# CONTROLSS_G3_EPWM24_CONTROLSS_G3_EPWM24 register map
Vendor: Texas Instruments
Registers are 16-bit, read-write, reset values left out (the file's numbers can be read two ways) unless marked. A register's access mark holds for its fields unless they carry their own. Offsets are as the file gives them; [hi:lo] are bit positions; {n}, {i} and the like mark numbered series.

## CONTROLSS_G3_EPWM24_CONTROLSS_G3_EPWM24 (part 4 of 4)
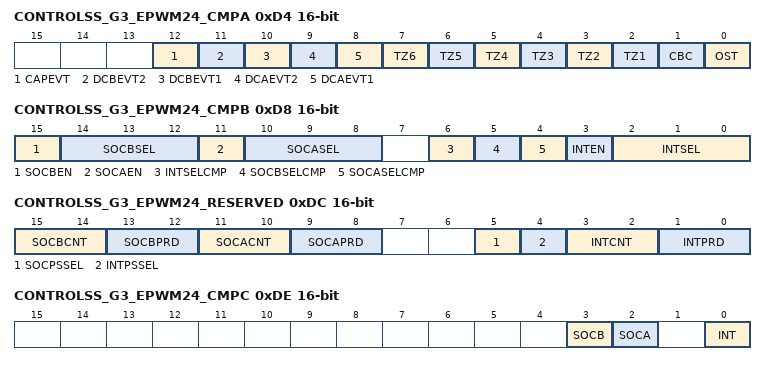
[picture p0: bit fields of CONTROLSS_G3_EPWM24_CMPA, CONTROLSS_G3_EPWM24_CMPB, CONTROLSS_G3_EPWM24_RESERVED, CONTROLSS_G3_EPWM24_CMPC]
0xD4 CONTROLSS_G3_EPWM24_CMPA
  [12] CAPEVT — CAPEVT Select 0: Disable TZ6 as a TRIPOUT source for this ePWM module 1: Enable TZ6 as a TRIPOUT source for this ePWM module
  [11] DCBEVT2 — DCBEVT2 Select 0: Disable TZ6 as a TRIPOUT source for this ePWM module 1: Enable TZ6 as a TRIPOUT source for this ePWM module
  [10] DCBEVT1 — DCBEVT1 Select 0: Disable TZ6 as a TRIPOUT source for this ePWM module 1: Enable TZ6 as a TRIPOUT source for this ePWM module
  [9] DCAEVT2 — DCAEVT2 Select 0: Disable TZ6 as a TRIPOUT source for this ePWM module 1: Enable TZ6 as a TRIPOUT source for this ePWM module
  [8] DCAEVT1 — DCAEVT1 Select 0: Disable TZ6 as a TRIPOUT source for this ePWM module 1: Enable TZ6 as a TRIPOUT source for this ePWM module
  [n+1] TZ{n} (n=1..6) — Trip-zone {n} (TZ{n}) Select 0: Disable TZ{n} as a TRIPOUT source for this ePWM module 1: Enable TZ{n} as a TRIPOUT source for this ePWM module
  [1] CBC — CBC Select 0: Disable TZ1 as a TRIPOUT source for this ePWM module 1: Enable TZ1 as a TRIPOUT source for this ePWM module
  [0] OST — OST Select 0: Disable TZ1 as a TRIPOUT source for this ePWM module 1: Enable TZ1 as a TRIPOUT source for this ePWM module
0xD8 CONTROLSS_G3_EPWM24_CMPB
  [15] SOCBEN — Enable the ADC Start of Conversion B (EPWMxSOCB) Pulse 0: Disable EPWMxSOCB. 1: Enable EPWMxSOCB pulse.
  [14:12] SOCBSEL — EPWMxSOCB Selection Options These bits determine when a EPWMxSOCB pulse will be generated. 000: Enable DCBEVT1.soc event 001: Enable event time-base counter equal to zero. (TBCTR = 0x00) 010: Enable event time-base counter equal to period (TBCTR = TBPRD) 011: Enable event time-base counter based on mixed events (ETSOCBMIX). ETSOCBMIX is configured in the ETSOCBMIXEN register. 100: Enable event time-base counter equal to CMPA when the timer is incrementing or CMPC when the timer is incrementing 101: Enable event time-base counter equal to CMPA when the timer is decrementing or CMPC when the timer is decrementing 110: Enable event: time-base counter equal to CMPB when the timer is incrementing or CMPD when the timer is incrementing 111: Enable event: time-base counter equal to CMPB when the timer is decrementing or CMPD when the timer is decrementing (*) Event selected is determined by SOCBSELCMP bit.
  [11] SOCAEN — Enable the ADC Start of Conversion A (EPWMxSOCA) Pulse 0: Disable EPWMxSOCA. 1: Enable EPWMxSOCA pulse.
  [10:8] SOCASEL — EPWMxSOCA Selection Options These bits determine when a EPWMxSOCA pulse will be generated. 000: Enable DCAEVT1.soc event 001: Enable event time-base counter equal to zero. (TBCTR = 0x00) 010: Enable event time-base counter equal to period (TBCTR = TBPRD) 011: Enable event time-base counter based on mixed events (ETSOCAMIX). ETSOCAMIX is configured in the ETSOCAMIXEN register. 100: Enable event time-base counter equal to CMPA when the timer is incrementing or CMPC when the timer is incrementing 101: Enable event time-base counter equal to CMPA when the timer is decrementing or CMPC when the timer is decrementing 110: Enable event: time-base counter equal to CMPB when the timer is incrementing or CMPD when the timer is incrementing 111: Enable event: time-base counter equal to CMPB when the timer is decrementing or CMPD when the timer is decrementing (*) Event selected is determined by SOCASELCMP bit.
  [6] INTSELCMP — EPWMxINT Compare Register Selection Options 0: Enable event time-base counter equal to CMPA when the timer is incrementing / Enable event time-base counter equal to CMPA when the timer is decrementing / Enable event: time-base counter equal to CMPB when the timer is incrementing / Enable event: time-base counter equal to CMPB when the timer is decrementing to INTSEL selection mux. 1: Enable event time-base counter equal to CMPC when the timer is incrementing / Enable event time-base counter equal to CMPC when the timer is decrementing / Enable event: time-base counter equal to CMPD when the timer is incrementing / Enable event: time-base counter equal to CMPD when the timer is decrementing to INTSEL selection mux.
  [5] SOCBSELCMP — EPWMxSOCB Compare Register Selection Options 0: Enable event time-base counter equal to CMPA when the timer is incrementing / Enable event time-base counter equal to CMPA when the timer is decrementing / Enable event: time-base counter equal to CMPB when the timer is incrementing / Enable event: time-base counter equal to CMPB when the timer is decrementing to SOCBSEL selection mux. 1: Enable event time-base counter equal to CMPC when the timer is incrementing / Enable event time-base counter equal to CMPC when the timer is decrementing / Enable event: time-base counter equal to CMPD when the timer is incrementing / Enable event: time-base counter equal to CMPD when the timer is decrementing to SOCBSEL selection mux.
  [4] SOCASELCMP — EPWMxSOCA Compare Register Selection Options 0: Enable event time-base counter equal to CMPA when the timer is incrementing / Enable event time-base counter equal to CMPA when the timer is decrementing / Enable event: time-base counter equal to CMPB when the timer is incrementing / Enable event: time-base counter equal to CMPB when the timer is decrementing to SOCASEL selection mux. 1: Enable event time-base counter equal to CMPC when the timer is incrementing / Enable event time-base counter equal to CMPC when the timer is decrementing / Enable event: time-base counter equal to CMPD when the timer is incrementing / Enable event: time-base counter equal to CMPD when the timer is decrementing to SOCASEL selection mux.
  [3] INTEN — Enable ePWM Interrupt (EPWMx_INT) Generation 0: Disable EPWMx_INT generation 1: Enable EPWMx_INT generation
  [2:0] INTSEL — ePWM Interrupt (EPWMx_INT) Selection Options 000: Reserved 001: Enable event time-base counter equal to zero. (TBCTR = 0x00) 010: Enable event time-base counter equal to period (TBCTR = TBPRD) 011: Enable event time-base counter based on mixed events (ETINTMIX). ETINTMIX is configured in the ETINTMIXEN register. 100: Enable event time-base counter equal to CMPA when the timer is incrementing or CMPC when the timer is incrementing 101: Enable event time-base counter equal to CMPA when the timer is decrementing or CMPC when the timer is decrementing 110: Enable event: time-base counter equal to CMPB when the timer is incrementing or CMPD when the timer is incrementing 111: Enable event: time-base counter equal to CMPB when the timer is decrementing or CMPD when the timer is decrementing (*) Event selected is determined by INTSELCMP bit.
0xDC CONTROLSS_G3_EPWM24_RESERVED access per field
  [15:14] SOCBCNT ro — ePWM ADC Start-of-Conversion B Event (EPWMxSOCB) Counter Register These bits indicate how many selected ETSEL[SOCBSEL] events have occurred: 00: No events have occurred. 01: 1 event has occurred. 10: 2 events have occurred. 11: 3 events have occurred.
  [13:12] SOCBPRD rw — ePWM ADC Start-of-Conversion B Event (EPWMxSOCB) Period Select These bits determine how many selected ETSEL[SOCBSEL] events need to occur before an EPWMxSOCB pulse is generated. To be generated, the pulse must be enabled (ETSEL[SOCBEN] = 1). The SOCB pulse will be generated even if the status flag is set from a previous start of conversion (ETFLG[SOCB] = 1). Once the SOCB pulse is generated, the ETPS[SOCBCNT] bits will automatically be cleared. 00: Disable the SOCB event counter. No EPWMxSOCB pulse will be generated 01: Generate the EPWMxSOCB pulse on the first event: ETPS[SOCBCNT] = 0,1 10: Generate the EPWMxSOCB pulse on the second event: ETPS[SOCBCNT] = 1,0 11: Generate the EPWMxSOCB pulse on the third event: ETPS[SOCBCNT] = 1,1
  [11:10] SOCACNT ro — ePWM ADC Start-of-Conversion A Event (EPWMxSOCA) Counter Register These bits indicate how many selected ETSEL[SOCASEL] events have occurred: 00: No events have occurred. 01: 1 event has occurred. 10: 2 events have occurred. 11: 3 events have occurred.
  [9:8] SOCAPRD rw — ePWM ADC Start-of-Conversion A Event (EPWMxSOCA) Period Select These bits determine how many selected ETSEL[SOCASEL] events need to occur before an EPWMxSOCA pulse is generated. To be generated, the pulse must be enabled (ETSEL[SOCAEN] = 1). The SOCA pulse will be generated even if the status flag is set from a previous start of conversion (ETFLG[SOCA] = 1). Once the SOCA pulse is generated, the ETPS[SOCACNT] bits will automatically be cleared. 00: Disable the SOCA event counter. No EPWMxSOCA pulse will be generated 01: Generate the EPWMxSOCA pulse on the first event: ETPS[SOCACNT] = 0,1 10: Generate the EPWMxSOCA pulse on the second event: ETPS[SOCACNT] = 1,0 11: Generate the EPWMxSOCA pulse on the third event: ETPS[SOCACNT] = 1,1
  [5] SOCPSSEL rw — EPWMxSOC A/B Pre-Scale Selection Bits 0: Selects ETPS [SOCACNT/SOCBCNT] and [SOCAPRD/SOCBPRD] registers to determine frequency of events (interrupt once every 0-3 events). 1: Selects ETSOCPS [SOCACNT2/SOCBCNT2] and [SOCAPRD2/SOCBPRD2] registers to determine frequency of events (interrupt once every 0-15 events).
  [4] INTPSSEL rw — EPWMxINTn Pre-Scale Selection Bits 0: Selects ETPS [INTCNT, and INTPRD] registers to determine frequency of events (interrupt once every 0-3 events). 1: Selects ETINTPS [ INTCNT2, and INTPRD2 ] registers to determine frequency of events (interrupt once every 0-15 events).
  [3:2] INTCNT ro — ePWM Interrupt Event (EPWMx_INT) Counter Register These bits indicate how many selected ETSEL[INTSEL] events have occurred. These bits are automatically cleared when an interrupt pulse is generated. If interrupts are disabled, ETSEL[INT] = 0 or the interrupt flag is set, ETFLG[INT] = 1, the counter will stop counting events when it reaches the period value ETPS[INTCNT] = ETPS[INTPRD]. 00: No events have occurred. 01: 1 event has occurred. 10: 2 events have occurred. 11: 3 events have occurred.
  [1:0] INTPRD rw — ePWM Interrupt (EPWMx_INT) Period Select These bits determine how many selected ETSEL[INTSEL] events need to occur before an interrupt is generated. To be generated, the interrupt must be enabled (ETSEL[INT] = 1). If the interrupt status flag is set from a previous interrupt (ETFLG[INT] = 1) then no interrupt will be generated until the flag is cleared via the ETCLR[INT] bit. This allows for one interrupt to be pending while another is still being serviced. Once the interrupt is generated, the ETPS[INTCNT] bits will automatically be cleared. Writing a INTPRD value that is the same as the current counter value will trigger an interrupt if it is enabled and the status flag is clear. Writing a INTPRD value that is less than the current counter value will result in an undefined state. If a counter event occurs at the same instant as a new zero or non-zero INTPRD value is written, the counter is incremented. 00: Disable the interruptevent counter. No interrupt will be generated and ETFRC[INT] is ignored. 01: Generate an interrupt on the first event INTCNT = 01 (first event) 10: Generate interrupt on ETPS[INTCNT] = 1,0 (second event) 11: Generate interrupt on ETPS[INTCNT] = 1,1 (third event)
0xDE CONTROLSS_G3_EPWM24_CMPC ro
  [3] SOCB — Latched ePWM ADC Start-of-Conversion A (EPWMxSOCB) Status Flag Unlike the ETFLG[INT] flag, the EPWMxSOCB output will continue to pulse even if the flag bit is set. 0: Indicates no event occurred 1: Indicates that a start of conversion pulse was generated on EPWMxSOCB. The EPWMxSOCB output will continue to be generated even if the flag bit is set.
  [2] SOCA — Latched ePWM ADC Start-of-Conversion A (EPWMxSOCA) Status Flag Unlike the ETFLG[INT] flag, the EPWMxSOCA output will continue to pulse even if the flag bit is set. 0: Indicates no event occurred 1: Indicates that a start of conversion pulse was generated on EPWMxSOCA. The EPWMxSOCA output will continue to be generated even if the flag bit is set.
  [0] INT — Latched ePWM Interrupt (EPWMx_INT) Status Flag 0: Indicates no event occurred 1: Indicates that an ePWMx interrupt (EPWMx_INT) was generated. No further interrupts will be generated until the flag bit is cleared. Up to one interrupt can be pending while the ETFLG[INT] bit is still set. If an interrupt is pending, it will not be generated until after the ETFLG[INT] bit is cleared.
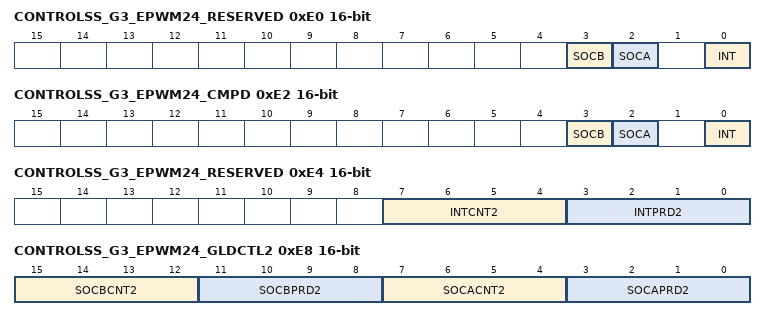
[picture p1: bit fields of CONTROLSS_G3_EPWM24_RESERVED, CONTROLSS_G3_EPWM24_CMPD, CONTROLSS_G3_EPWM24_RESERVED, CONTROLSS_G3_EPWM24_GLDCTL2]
0xE0 CONTROLSS_G3_EPWM24_RESERVED access not given
  [3] SOCB — ePWM ADC Start-of-Conversion A (EPWMxSOCB) Flag Clear Bit 0: Writing a 0 has no effect. Always reads back a 0 1: Clears the ETFLG[SOCB] flag bit (access RW RRETURNS0S)
  [2] SOCA — ePWM ADC Start-of-Conversion A (EPWMxSOCA) Flag Clear Bit 0: Writing a 0 has no effect. Always reads back a 0 1: Clears the ETFLG[SOCA] flag bit (access RW RRETURNS0S)
  [0] INT — ePWM Interrupt (EPWMx_INT) Flag Clear Bit 0: Writing a 0 has no effect. Always reads back a 0 1: Clears the ETFLG[INT] flag bit and enable further interrupts pulses to be generated (access RW RRETURNS0S)
0xE2 CONTROLSS_G3_EPWM24_CMPD access not given
  [3] SOCB — SOCB Force Bit The SOCB pulse will only be generated if the event is enabled in the ETSEL register. The ETFLG[SOCB] flag bit will be set regardless. 0: Writing 0 to this bit will be ignored. Always reads back a 0. 1: Generates a pulse on EPWMxSOCB and set the SOCBFLG bit. This bit is used for test purposes. (access RW RRETURNS0S)
  [2] SOCA — SOCA Force Bit The SOCA pulse will only be generated if the event is enabled in the ETSEL register. The ETFLG[SOCA] flag bit will be set regardless. 0: Writing 0 to this bit will be ignored. Always reads back a 0. 1: Generates a pulse on EPWMxSOCA and set the SOCAFLG bit. This bit is used for test purposes. (access RW RRETURNS0S)
  [0] INT — INT Force Bit The interrupt will only be generated if the event is enabled in the ETSEL register. The INT flag bit will be set regardless. 0: Writing 0 to this bit will be ignored. Always reads back a 0. 1: Generates an interrupt on EPWMxINT and set the INT flag bit. This bit is used for test purposes. (access RW RRETURNS0S)
0xE4 CONTROLSS_G3_EPWM24_RESERVED access per field
  [7:4] INTCNT2 ro — EPWMxINT Counter 2 When ETPS[INTPSSEL]=1, these bits indicate how many selected events have occurred: 0000: No events 0001: 1 event 0010: 2 events 0011: 3 events 0100: 4 events ... 1111: 15 events
  [3:0] INTPRD2 rw — EPWMxINT Period 2 Select When ETPS[INTPSSEL] = 1, these bits select how many selected events need to occur before an interrupt is generated: 0000: Disable counter 0001: Generate interrupt on INTCNT = 1 (first event) 0010: Generate interrupt on INTCNT = 2 (second event) 0011: Generate interrupt on INTCNT = 3 (third event) 0100: Generate interrupt on INTCNT = 4 (fourth event) ... 1111: Generate interrupt on INTCNT = 15 (fifteenth event)
0xE8 CONTROLSS_G3_EPWM24_GLDCTL2 access per field
  [15:12] SOCBCNT2 ro — EPWMxSOCB Counter 2 When ETPS[SOCPSSEL] = 1, these bits indicate how many selected events have occurred: 0000: No events 0001: 1 event 0010: 2 events 0011: 3 events 0100: 4 events ... 1111: 15 events
  [11:8] SOCBPRD2 rw — EPWMxSOCB Period 2 Select When ETPS[SOCPSSEL] = 1, these bits select how many selected event need to occur before an SOCB pulse is generated: 0000: Disable counter 0001: Generate interrupt on SOCBCNT2 = 1 (first event) 0010: Generate interrupt on SOCBCNT2 = 2 (second event) 0011: Generate interrupt on SOCBCNT2 = 3 (third event) 0100: Generate interrupt on SOCBCNT2 = 4 (fourth event) ... 1111: Generate interrupt on SOCBCNT2 = 15 (fifteenth event)
  [7:4] SOCACNT2 ro — EPWMxSOCA Counter 2 When ETPS[SOCPSSEL] = 1, these bits indicate how many selected events have occurred: 0000: No events 0001: 1 event 0010: 2 events 0011: 3 events 0100: 4 events ... 1111: 15 events
  [3:0] SOCAPRD2 rw — EPWMxSOCA Period 2 Select When ETPS[SOCPSSEL] = 1, these bits select how many selected event need to occur before an SOCA pulse is generated: 0000: Disable counter 0001: Generate interrupt on SOCACNT2 = 1 (first event) 0010: Generate interrupt on SOCACNT2 = 2 (second event) 0011: Generate interrupt on SOCACNT2 = 3 (third event) 0100: Generate interrupt on SOCACNT2 = 4 (fourth event) ... 1111: Generate interrupt on SOCACNT2 = 15 (fifteenth event)
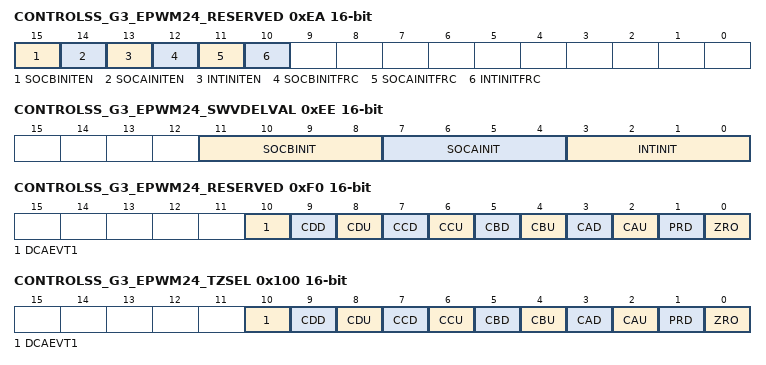
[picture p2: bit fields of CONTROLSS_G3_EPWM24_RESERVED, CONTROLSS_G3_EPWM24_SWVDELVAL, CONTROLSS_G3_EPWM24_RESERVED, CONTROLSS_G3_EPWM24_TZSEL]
0xEA CONTROLSS_G3_EPWM24_RESERVED access not given
  [15] SOCBINITEN rw — EPWMxSOCB Counter 2 Initialization Enable 0: Has no effect. 1: Enable initialization of EPWMxSOCB counter with contents of ETCNTINIT[SOCBINIT] on a SYNC event or software force.
  [14] SOCAINITEN rw — EPWMxSOCA Counter 2 Initialization Enable 0: Has no effect. 1: Enable initialization of EPWMxSOCA counter with contents of ETCNTINIT[SOCAINIT] on a SYNC event or software force.
  [13] INTINITEN rw — EPWMxINT Counter 2 Initialization Enable 0: Has no effect. 1: Enable initialization of EPWMxINT counter 2 with contents of ETCNTINIT[INTINIT] on a SYNC event or software force.
  [12] SOCBINITFRC — EPWMxSOCB Counter 2 Initialization Force 0: Has no effect. 1: This bit forces the ET EPWMxSOCB counter to be initialized with the contents of ETCNTINIT[SOCBINIT]. (access RW RRETURNS0S)
  [11] SOCAINITFRC — EPWMxSOCA Counter 2 Initialization Force 0: Has no effect. 1: This bit forces the ET EPWMxSOCA counter to be initialized with the contents of ETCNTINIT[SOCAINIT]. (access RW RRETURNS0S)
  [10] INTINITFRC — EPWMxINT Counter 2 Initialization Force 0: Has no effect. 1: This bit forces the ET EPWMxINT counter to be initialized with the contents of ETCNTINIT[INTINIT]. (access RW RRETURNS0S)
0xEE CONTROLSS_G3_EPWM24_SWVDELVAL
  [11:8] SOCBINIT — EPWMxSOCB Counter 2 Initialization Bits The ET EPWMxSOCB counter is initialized with the contents of this register on an ePWM SYNC event or a software force.
  [7:4] SOCAINIT — EPWMxSOCA Counter 2 Initialization Bits The ET EPWMxSOCA counter is initialized with the contents of this register on an ePWM SYNC event or a software force.
  [3:0] INTINIT — EPWMxINT Counter 2 Initialization Bits The ET EPWMxINT counter is initialized with the contents of this register on an ePWM SYNC event or a software force.
0xF0 CONTROLSS_G3_EPWM24_RESERVED
  [10] DCAEVT1 — Enable DCAEVT1.inter to the mixed ET interrupt trigger signal (ETINTMIX). 0: DCAEVT1.soc event is not enabled 1: Enable DCAEVT1.soc event
  [9] CDD — Enable event time-base counter equal to CMPD when the timer is decrementing to the mixed ET interrupt trigger signal (ETINTMIX). 0: CMPD down-count match enable event is not enabled 1: Enable CMPD down-count match enable event
  [8] CDU — Enable event time-base counter equal to CMPD when the timer is incrementing to the mixed ET interrupt trigger signal (ETINTMIX). 0: CMPD up-count match enable event is not enabled 1: Enable CMPD up-count match enable event
  [7] CCD — Enable event time-base counter equal to CMPC when the timer is decrementing to the mixed ET interrupt trigger signal (ETINTMIX). 0: CMPC down-count match enable event is not enabled 1: Enable CMPC down-count match enable event
  [6] CCU — Enable event time-base counter equal to CMPC when the timer is incrementing to the mixed ET interrupt trigger signal (ETINTMIX). 0: CMPC up-count match enable event is not enabled 1: Enable CMPC up-count match enable event
  [5] CBD — Enable event time-base counter equal to CMPB when the timer is decrementing to the mixed ET interrupt trigger signal (ETINTMIX). 0: CMPB down-count match enable event is not enabled 1: Enable CMPB down-count match enable event
  [4] CBU — Enable event time-base counter equal to CMPB when the timer is incrementing to the mixed ET interrupt trigger signal (ETINTMIX). 0: CMPB up-count match enable event is not enabled 1: Enable CMPB up-count match enable event
  [3] CAD — Enable event time-base counter equal to CMPA when the timer is decrementing to the mixed ET interrupt trigger signal (ETINTMIX). 0: CMPA down-count match enable event is not enabled 1: Enable CMPA down-count match enable event
  [2] CAU — Enable event time-base counter equal to CMPA when the timer is incrementing to the mixed ET interrupt trigger signal (ETINTMIX). 0: CMPA up-count match enable event is not enabled 1: Enable CMPA up-count match enable event
  [1] PRD — Enable event time-base counter equal to period (TBCTR = TBPRD) to the mixed ET interrupt trigger signal (ETINTMIX). 0: Period match event is not enabled 1: Enable period match event
  [0] ZRO — Enable event time-base counter equal to zero (TBCTR = 0x00) to the mixed ET interrupt trigger signal (ETINTMIX). 0: Zero match event is not enabled 1: Enable zero match event
0x100 CONTROLSS_G3_EPWM24_TZSEL
  [10] DCAEVT1 — Enable DCAEVT1.inter to the mixed ET SOCA trigger signal (ETSOCAMIX). 0: DCAEVT1.soc event is not enabled 1: Enable DCAEVT1.soc event
  [9] CDD — Enable event time-base counter equal to CMPD when the timer is decrementing to the mixed ET SOCA trigger signal (ETSOCAMIX). 0: CMPD down-count match enable event is not enabled 1: Enable CMPD down-count match enable event
  [8] CDU — Enable event time-base counter equal to CMPD when the timer is incrementing to the mixed ET SOCA trigger signal (ETSOCAMIX). 0: CMPD up-count match enable event is not enabled 1: Enable CMPD up-count match enable event
  [7] CCD — Enable event time-base counter equal to CMPC when the timer is decrementing to the mixed ET SOCA trigger signal (ETSOCAMIX). 0: CMPC down-count match enable event is not enabled 1: Enable CMPC down-count match enable event
  [6] CCU — Enable event time-base counter equal to CMPC when the timer is incrementing to the mixed ET SOCA trigger signal (ETSOCAMIX). 0: CMPC up-count match enable event is not enabled 1: Enable CMPC up-count match enable event
  [5] CBD — Enable event time-base counter equal to CMPB when the timer is decrementing to the mixed ET SOCA trigger signal (ETSOCAMIX). 0: CMPB down-count match enable event is not enabled 1: Enable CMPB down-count match enable event
  [4] CBU — Enable event time-base counter equal to CMPB when the timer is incrementing to the mixed ET SOCA trigger signal (ETSOCAMIX). 0: CMPB up-count match enable event is not enabled 1: Enable CMPB up-count match enable event
  [3] CAD — Enable event time-base counter equal to CMPA when the timer is decrementing to the mixed ET SOCA trigger signal (ETSOCAMIX). 0: CMPA down-count match enable event is not enabled 1: Enable CMPA down-count match enable event
  [2] CAU — Enable event time-base counter equal to CMPA when the timer is incrementing to the mixed ET SOCA trigger signal (ETSOCAMIX). 0: CMPA up-count match enable event is not enabled 1: Enable CMPA up-count match enable event
  [1] PRD — Enable event time-base counter equal to period (TBCTR = TBPRD) to the mixed ET SOCA trigger signal (ETSOCAMIX). 0: Period match event is not enabled 1: Enable period match event
  [0] ZRO — Enable event time-base counter equal to zero (TBCTR = 0x00) to the mixed ET SOCA trigger signal (ETSOCAMIX). 0: Zero match event is not enabled 1: Enable zero match event
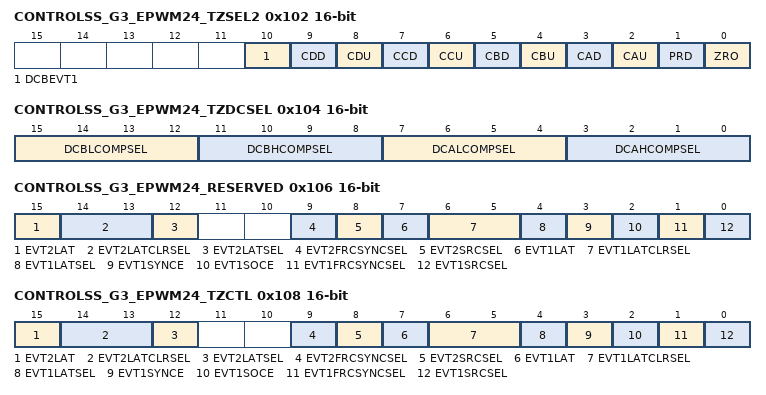
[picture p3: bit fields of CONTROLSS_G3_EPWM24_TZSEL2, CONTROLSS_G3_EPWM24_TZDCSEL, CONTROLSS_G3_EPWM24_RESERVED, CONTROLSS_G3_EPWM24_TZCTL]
0x102 CONTROLSS_G3_EPWM24_TZSEL2
  [10] DCBEVT1 — Enable DCBEVT1.inter to the mixed ET SOCB trigger signal (ETSOCBMIX). 0: DCBEVT1.soc event is not enabled 1: Enable DCBEVT1.soc event
  [9] CDD — Enable event time-base counter equal to CMPD when the timer is decrementing to the mixed ET SOCB trigger signal (ETSOCBMIX). 0: CMPD down-count match enable event is not enabled 1: Enable CMPD down-count match enable event
  [8] CDU — Enable event time-base counter equal to CMPD when the timer is incrementing to the mixed ET SOCB trigger signal (ETSOCBMIX). 0: CMPD up-count match enable event is not enabled 1: Enable CMPD up-count match enable event
  [7] CCD — Enable event time-base counter equal to CMPC when the timer is decrementing to the mixed ET SOCB trigger signal (ETSOCBMIX). 0: CMPC down-count match enable event is not enabled 1: Enable CMPC down-count match enable event
  [6] CCU — Enable event time-base counter equal to CMPC when the timer is incrementing to the mixed ET SOCB trigger signal (ETSOCBMIX). 0: CMPC up-count match enable event is not enabled 1: Enable CMPC up-count match enable event
  [5] CBD — Enable event time-base counter equal to CMPB when the timer is decrementing to the mixed ET SOCB trigger signal (ETSOCBMIX). 0: CMPB down-count match enable event is not enabled 1: Enable CMPB down-count match enable event
  [4] CBU — Enable event time-base counter equal to CMPB when the timer is incrementing to the mixed ET SOCB trigger signal (ETSOCBMIX). 0: CMPB up-count match enable event is not enabled 1: Enable CMPB up-count match enable event
  [3] CAD — Enable event time-base counter equal to CMPA when the timer is decrementing to the mixed ET SOCB trigger signal (ETSOCBMIX). 0: CMPA down-count match enable event is not enabled 1: Enable CMPA down-count match enable event
  [2] CAU — Enable event time-base counter equal to CMPA when the timer is incrementing to the mixed ET SOCB trigger signal (ETSOCBMIX). 0: CMPA up-count match enable event is not enabled 1: Enable CMPA up-count match enable event
  [1] PRD — Enable event time-base counter equal to period (TBCTR = TBPRD) to the mixed ET SOCB trigger signal (ETSOCBMIX). 0: Period match event is not enabled 1: Enable period match event
  [0] ZRO — Enable event time-base counter equal to zero (TBCTR = 0x00) to the mixed ET SOCB trigger signal (ETSOCBMIX). 0: Zero match event is not enabled 1: Enable zero match event
0x104 CONTROLSS_G3_EPWM24_TZDCSEL
  [15:12] DCBLCOMPSEL — Digital Compare B Low Input Select Bits 0000: TRIPIN1 0001: TRIPIN2 0010: TRIPIN3 0011: TRIPIN4 ... 1011: TRIPIN12 1100: Reserved 1101: TRIPIN14 1110: TRIPIN15 1111: Trip combination input (all trip inputs selected by DCBLTRIPSEL register ORed together)
  [11:8] DCBHCOMPSEL — Digital Compare B High Input Select Bits 0000: TRIPIN1 0001: TRIPIN2 0010: TRIPIN3 0011: TRIPIN4 ... 1011: TRIPIN12 1100: Reserved 1101: TRIPIN14 1110: TRIPIN15 1111: Trip combination input (all trip inputs selected by DCBHTRIPSEL register ORed together)
  [7:4] DCALCOMPSEL — Digital Compare A Low Input Select Bits 0000: TRIPIN1 0001: TRIPIN2 0010: TRIPIN3 0011: TRIPIN4 ... 1011: TRIPIN12 1100: Reserved 1101: TRIPIN14 1110: TRIPIN15 1111: Trip combination input (all trip inputs selected by DCALTRIPSEL register ORed together)
  [3:0] DCAHCOMPSEL — Digital Compare A High Input Select Bits 0000: TRIPIN1 0001: TRIPIN2 0010: TRIPIN3 0011: TRIPIN4 ... 1011: TRIPIN12 1100: Reserved 1101: TRIPIN14 1110: TRIPIN15 1111: Trip combination input (all trip inputs selected by DCAHTRIPSEL register ORed together)
0x106 CONTROLSS_G3_EPWM24_RESERVED access per field
  [15] EVT2LAT ro — Indicates the status of DCAEVT2LAT signal. 0 The DCAEVT2LAT latch is cleared. 1 The DCAEVT2LAT latch is set.
  [14:13] EVT2LATCLRSEL rw — DCAEVT2 Latched clear source select: 00 CNT_ZERO event clears DCAEVT2 latch. 01 PRD_EQ event clears DCAEVT2 latch. 10 CNT_ZERO event or PRD_EQ event clears DCAEVT2 latch. 11 Reserved.
  [12] EVT2LATSEL rw — DCAEVT2 Latched signal select: 0 Does not select the DCAEVT2 latched signal (Refer figure 'Modifications to DCAEVT1.force/DCAEVT2.force generation.') as source of DCAEVT2.force. 1 Selects the DCAEVT2 latched signal as source of DCAEVT2.force.
  [9] EVT2FRCSYNCSEL rw — DCAEVT2 Force Synchronization Signal Select 0: Source is synchronized with EPWMCLK 1: Source is passed through asynchronously
  [8] EVT2SRCSEL rw — DCAEVT2 Source Signal Select 0: Source Is DCAEVT2 Signal 1: Source Is DCEVTFILT Signal
  [7] EVT1LAT ro — Indicates the status of DCAEVT1LAT signal. 0 The DCAEVT1LAT latch is cleared. 1 The DCAEVT1LAT latch is set.
  [6:5] EVT1LATCLRSEL rw — DCAEVT1 Latched clear source select: 00 CNT_ZERO event clears DCAEVT1 latch. 01 PRD_EQ event clears DCAEVT1 latch. 10 CNT_ZERO event or PRD_EQ event clears DCAEVT1 latch. 11 Reserved.
  [4] EVT1LATSEL rw — DCAEVT1 Latched signal select: 0 Does not select the DCAEVT1 latched signal (Refer figure 'Modifications to DCAEVT1.force/DCAEVT2.force generation.') as source of DCAEVT1.force. 1 Selects the DCAEVT1 latched signal as source of DCAEVT1.force.
  [3] EVT1SYNCE rw — DCAEVT1 SYNC, Enable/Disable 0: SYNC Generation Disabled 1: SYNC Generation Enabled
  [2] EVT1SOCE rw — DCAEVT1 SOC, Enable/Disable 0: SOC Generation Disabled 1: SOC Generation Enabled
  [1] EVT1FRCSYNCSEL rw — DCAEVT1 Force Synchronization Signal Select 0: Source is synchronized with EPWMCLK 1: Source is passed through asynchronously
  [0] EVT1SRCSEL rw — DCAEVT1 Source Signal Select 0: Source Is DCAEVT1 Signal 1: Source Is DCEVTFILT Signal
0x108 CONTROLSS_G3_EPWM24_TZCTL access per field
  [15] EVT2LAT ro — Indicates the status of DCBEVT2LAT signal. 0 The DCBEVT2LAT latch is cleared. 1 The DCBEVT2LAT latch is set.
  [14:13] EVT2LATCLRSEL rw — DCBEVT2 Latched clear source select: 00 CNT_ZERO event clears DCBEVT2 latch. 01 PRD_EQ event clears DCBEVT2 latch. 10 CNT_ZERO event or PRD_EQ event clears DCBEVT2 latch. 11 Reserved.
  [12] EVT2LATSEL rw — DCBEVT2 Latched signal select: 0 Does not select the DCBEVT2 latched signal (Refer figure 'Modifications to DCBEVT1.force/DCBEVT2.force generation.') as source of DCBEVT2.force. 1 Selects the DCBEVT2 latched signal as source of DCBEVT2.force.
  [9] EVT2FRCSYNCSEL rw — DCBEVT2 Force Synchronization Signal Select 0: Source is synchronized with EPWMCLK 1: Source is passed through asynchronously
  [8] EVT2SRCSEL rw — DCBEVT2 Source Signal Select 0: Source Is DCBEVT2 Signal 1: Source Is DCEVTFILT Signal
  [7] EVT1LAT ro — Indicates the status of DCBEVT1LAT signal. 0 The DCBEVT1LAT latch is cleared. 1 The DCBEVT1LAT latch is set.
  [6:5] EVT1LATCLRSEL rw — DCBEVT1 Latched clear source select: 00 CNT_ZERO event clears DCBEVT1 latch. 01 PRD_EQ event clears DCBEVT1 latch. 10 CNT_ZERO event or PRD_EQ event clears DCBEVT1 latch. 11 Reserved.
  [4] EVT1LATSEL rw — DCBEVT1 Latched signal select: 0 Does not select the DCBEVT1 latched signal (Refer figure 'Modifications to DCBEVT1.force/DCBEVT2.force generation.') as source of DCBEVT1.force. 1 Selects the DCBEVT1 latched signal as source of DCBEVT1.force.
  [3] EVT1SYNCE rw — DCBEVT1 SYNC, Enable/Disable 0: SYNC Generation Disabled 1: SYNC Generation Enabled
  [2] EVT1SOCE rw — DCBEVT1 SOC, Enable/Disable 0: SOC Generation Disabled 1: SOC Generation Enabled
  [1] EVT1FRCSYNCSEL rw — DCBEVT1 Force Synchronization Signal Select 0: Source is synchronized with EPWMCLK 1: Source is passed through asynchronously
  [0] EVT1SRCSEL rw — DCBEVT1 Source Signal Select 0: Source Is DCBEVT1 Signal 1: Source Is DCEVTFILT Signal
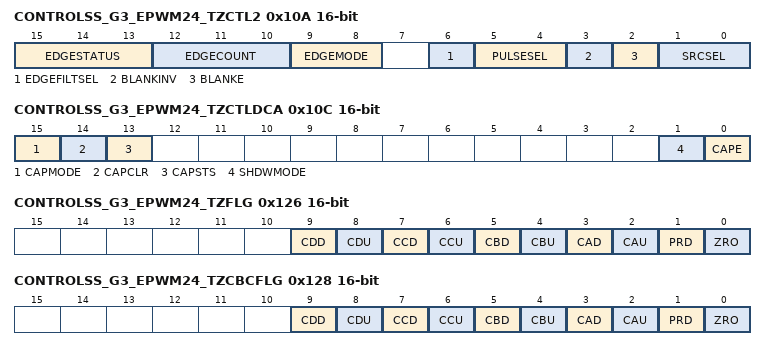
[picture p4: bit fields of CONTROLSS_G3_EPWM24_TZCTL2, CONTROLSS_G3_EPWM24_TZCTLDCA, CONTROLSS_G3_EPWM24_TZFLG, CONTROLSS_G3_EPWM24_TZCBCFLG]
0x10A CONTROLSS_G3_EPWM24_TZCTL2 access per field
  [15:13] EDGESTATUS ro — Edge Status: These bits reflect the total number of edges currently captured. When the value matches the EDGECOUNT, the status bits are set to zero. and a TBCLK wide pulse is generated which can then be output on the DCEVTFILT signal. The edge counter can be reset by writing 000 to the EDGECOUNT value:
  [12:10] EDGECOUNT rw — Edge Count: These bits select how many edges to count before generating a TBCLK wide pulse on the DCEVTFILT signal: 000: no edges, reset current EDGESTATUS bits to 0,0,0 001: 1 edge 010: 2 edges 011: 3 edges 100: 4 edges 101: 5 edges 110: 6 edges 111: 7 edges
  [9:8] EDGEMODE rw — Edge Mode Select: 00: Low To High Edge 01: High To Low Edge 10: Both Edges 11: Reserved
  [6] EDGEFILTSEL rw — Edge Filter Select: 0: Edge Filter Not Selected 1: Edge Filter Selected
  [5:4] PULSESEL rw — Pulse Select For Blanking & Capture Alignment 00: Time-base counter equal to period (TBCTR = TBPRD) 01: Time-base counter equal to zero (TBCTR = 0x00) 10: Time-base counter equal to zero (TBCTR = 0x00) or period (TBCTR = TBPRD) 11: Blank Pulse Mix
  [3] BLANKINV rw — Blanking Window Inversion 0: Blanking window not inverted 1: Blanking window inverted
  [2] BLANKE rw — Blanking Window Enable/Disable 0: Blanking window is disabled 1: Blanking window is enabled
  [1:0] SRCSEL rw — Filter Block Signal Source Select 00: Source Is DCAEVT1 Signal 01: Source Is DCAEVT2 Signal 10: Source Is DCBEVT1 Signal 11: Source Is DCBEVT2 Signal
0x10C CONTROLSS_G3_EPWM24_TZCTLDCA access not given
  [15] CAPMODE rw — Counter Capture Mode 0: When a DCEVTFILT occurs and the counter capture is enabled, then the current TBCNT value is captured in the active register. When the respective trip event occurs, further trip (capture) events are ignored until the next PRD_eq or CNT_zero event (as selected by the PULSESEL bit in the DCFCTL register) re-triggers the capture mechanism. If active mode is enabled, via SHDWMODE bit in DCCAPCTL register, CPU reads of this register will return the active register value. If shadow mode is enabled, via SHDWMODE bit in DCCAPCTL register, the active register is copied to the shadow register on the PRD_eq or CNT_zero event (whichever is selected by PULSESEL bit in DCFCTL register). CPU reads of this register will return the shadow register value. 1: When a DCEVTFILT occurs and the counter capture is enabled, then the current TBCNT value is captured in the active register. When the respective trip event occurs - itwill set the CAPSTS flag and further trip (capture) events are ignored until this bit is cleared. CAPSTS can be cleared by writing to CAPCLR bit in DCCAPCTL register and it re-triggers the capture mechanism. If active mode is enabled, via SHDWMODE bit in DCCAPCTL register, CPU reads of this register will return the active register value. If shadow mode is enabled, via SHDWMODE bit in DCCAPCTL register, the active register is copied to the shadow register on the PRD_eq or CNT_zero event (whichever is selected by PULSESEL bit in DCFCTL register). CPU reads of this register will return the shadow register value.
  [14] CAPCLR — DC Capture Latched Status Clear Flag 0: Writing a 0 has no effect. 1: Writing a 1 will clear this CAPSTS (set) condition. (access RW RRETURNS0S)
  [13] CAPSTS ro — Latched Status Flag for Capture Event 0: No DC capture event occurred. 1: A DC capture event has occurred.
  [1] SHDWMODE rw — TBCTR Counter Capture Shadow Select Mode 0: Enable shadow mode. The DCCAP active register is copied to shadow register on a TBCTR = TBPRD or TBCTR = zero event as defined by the DCFCTL[PULSESEL] bit. CPU reads of the DCCAP register will return the shadow register contents. 1: Active Mode. In this mode the shadow register is disabled. CPU reads from the DCCAP register will always return the active register contents.
  [0] CAPE rw — TBCTR Counter Capture Enable/Disable 0: Disable the time-base counter capture. 1: Enable the time-base counter capture.
0x10E CONTROLSS_G3_EPWM24_TZCTLDCB
  [15:0] DCFOFFSET — Blanking Window Offset These 16-bits specify the number of TBCLK cycles from the blanking window reference to the point when the blanking window is applied. The blanking window reference is either period or zero as defined by the DCFCTL[PULSESEL] bit. This offset register is shadowed and the active register is loaded at the reference point defined by DCFCTL[PULSESEL]. The offset counter is also initialized and begins to count down when the active register is loaded. When the counter expires, the blanking window is applied. If the blanking window is currently active, then the blanking window counter is restarted.
0x110 CONTROLSS_G3_EPWM24_RESERVED ro
  [15:0] DCFOFFSETCNT — Blanking Offset Counter These 16-bits are read only and indicate the current value of the offset counter. The counter counts down to zero and then stops until it is re-loaded on the next period or zero event as defined by the DCFCTL[PULSESEL] bit. The offset counter is not affected by the free/soft emulation bits. That is, it will always continue to count down if the device is halted by a emulation stop.
0x11A CONTROLSS_G3_EPWM24_TZEINT
  [15:0] DCFWINDOW — Blanking Window Width 00h: No blanking window is generated. 01-FFFFh: Specifies the width of the blanking window in TBCLK cycles. The blanking window begins when the offset counter expires. When this occurs, the window counter is loaded and begins to count down. If the blanking window is currently active and the offset counter expires, the blanking window counter is not restarted and the blanking window is cut short prematurely. Care should be taken to avoid this situation. The blanking window can cross a PWM period boundary.
0x11C CONTROLSS_G3_EPWM24_RESERVED ro
  [15:0] DCFWINDOWCNT — Blanking Window Counter These 16 bits are read only and indicate the current value of the window counter. The counter counts down to zero and then stops until it is re-loaded when the offset counter reaches zero again.
0x126 CONTROLSS_G3_EPWM24_TZFLG
  [9] CDD — Enable event time-base counter equal to CMPD when the timer is decrementing to the blanking window trigger (BLANKPULSEMIX). 0: CMPD down-count match enable event is not enabled 1: Enable CMPD down-count match enable event
  [8] CDU — Enable event time-base counter equal to CMPD when the timer is incrementing to the blanking window trigger (BLANKPULSEMIX). 0: CMPD up-count match enable event is not enabled 1: Enable CMPD up-count match enable event
  [7] CCD — Enable event time-base counter equal to CMPC when the timer is decrementing to the blanking window trigger (BLANKPULSEMIX). 0: CMPC down-count match enable event is not enabled 1: Enable CMPC down-count match enable event
  [6] CCU — Enable event time-base counter equal to CMPC when the timer is incrementing to the blanking window trigger (BLANKPULSEMIX). 0: CMPC up-count match enable event is not enabled 1: Enable CMPC up-count match enable event
  [5] CBD — Enable event time-base counter equal to CMPB when the timer is decrementing to the blanking window trigger (BLANKPULSEMIX). 0: CMPB down-count match enable event is not enabled 1: Enable CMPB down-count match enable event
  [4] CBU — Enable event time-base counter equal to CMPB when the timer is incrementing to the mixed ET interrupt trigger signal (BLANKPULSEMIX). 0: CMPB up-count match enable event is not enabled 1: Enable CMPB up-count match enable event
  [3] CAD — Enable event time-base counter equal to CMPA when the timer is decrementing to the blanking window trigger (BLANKPULSEMIX). 0: CMPA down-count match enable event is not enabled 1: Enable CMPA down-count match enable event
  [2] CAU — Enable event time-base counter equal to CMPA when the timer is incrementing to the blanking window trigger (BLANKPULSEMIX). 0: CMPA up-count match enable event is not enabled 1: Enable CMPA up-count match enable event
  [1] PRD — Enable event time-base counter equal to period (TBCTR = TBPRD) to the blanking window trigger (BLANKPULSEMIX). 0: Period match event is not enabled 1: Enable period match event
  [0] ZRO — Enable event time-base counter equal to zero (TBCTR = 0x00) to the blanking window trigger (BLANKPULSEMIX). 0: Zero match event is not enabled 1: Enable zero match event
0x128 CONTROLSS_G3_EPWM24_TZCBCFLG
  [9] CDD — Enable event time-base counter equal to CMPD when the timer is decrementing to the blanking window trigger (DCCAPMIX). 0: CMPD down-count match enable event is not enabled 1: Enable CMPD down-count match enable event
  [8] CDU — Enable event time-base counter equal to CMPD when the timer is incrementing to the blanking window trigger (DCCAPMIX). 0: CMPD up-count match enable event is not enabled 1: Enable CMPD up-count match enable event
  [7] CCD — Enable event time-base counter equal to CMPC when the timer is decrementing to the blanking window trigger (DCCAPMIX). 0: CMPC down-count match enable event is not enabled 1: Enable CMPC down-count match enable event
  [6] CCU — Enable event time-base counter equal to CMPC when the timer is incrementing to the blanking window trigger (DCCAPMIX). 0: CMPC up-count match enable event is not enabled 1: Enable CMPC up-count match enable event
  [5] CBD — Enable event time-base counter equal to CMPB when the timer is decrementing to the blanking window trigger (DCCAPMIX). 0: CMPB down-count match enable event is not enabled 1: Enable CMPB down-count match enable event
  [4] CBU — Enable event time-base counter equal to CMPB when the timer is incrementing to the mixed ET interrupt trigger signal (DCCAPMIX). 0: CMPB up-count match enable event is not enabled 1: Enable CMPB up-count match enable event
  [3] CAD — Enable event time-base counter equal to CMPA when the timer is decrementing to the blanking window trigger (DCCAPMIX). 0: CMPA down-count match enable event is not enabled 1: Enable CMPA down-count match enable event
  [2] CAU — Enable event time-base counter equal to CMPA when the timer is incrementing to the blanking window trigger (DCCAPMIX). 0: CMPA up-count match enable event is not enabled 1: Enable CMPA up-count match enable event
  [1] PRD — Enable event time-base counter equal to period (TBCTR = TBPRD) to the blanking window trigger (DCCAPMIX). 0: Period match event is not enabled 1: Enable period match event
  [0] ZRO — Enable event time-base counter equal to zero (TBCTR = 0x00) to the blanking window trigger (DCCAPMIX). 0: Zero match event is not enabled 1: Enable zero match event
